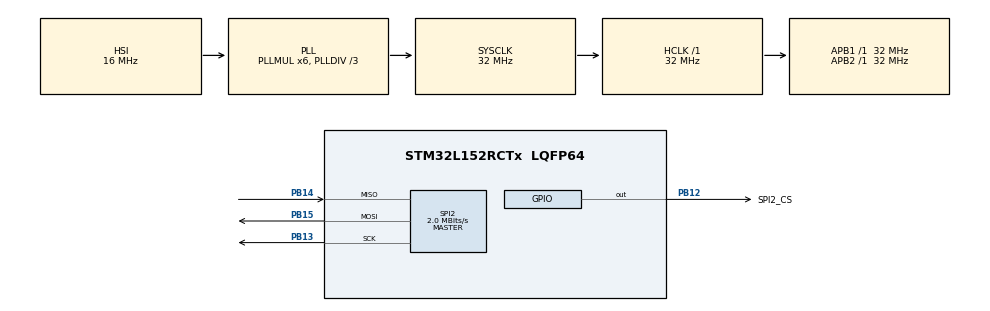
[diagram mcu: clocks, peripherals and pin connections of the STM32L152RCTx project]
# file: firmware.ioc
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Mcu.Family=STM32L1
Mcu.Name=STM32L152RCTx
Mcu.Package=LQFP64
NVIC.PriorityGroup=NVIC_PRIORITYGROUP_4
PB12.GPIO_Label=SPI2_CS
PB12.GPIO_PuPd=GPIO_PULLUP
PB12.GPIO_Speed=GPIO_SPEED_FREQ_VERY_HIGH
PB12.PinState=GPIO_PIN_SET
PB12.Signal=GPIO_Output
PB13.GPIO_PuPd=GPIO_PULLUP
PB13.Mode=Full_Duplex_Master
PB13.Signal=SPI2_SCK
PB14.GPIO_PuPd=GPIO_PULLUP
PB14.Mode=Full_Duplex_Master
PB14.Signal=SPI2_MISO
PB15.GPIO_PuPd=GPIO_PULLUP
PB15.Mode=Full_Duplex_Master
PB15.Signal=SPI2_MOSI
ProjectManager.HeapSize=0x200
ProjectManager.StackSize=0x400
ProjectManager.TargetToolchain=MDK-ARM V5
RCC.AHBFreq_Value=32000000
RCC.APB1Freq_Value=32000000
RCC.APB1TimFreq_Value=32000000
RCC.APB2Freq_Value=32000000
RCC.APB2TimFreq_Value=32000000
RCC.HCLKFreq_Value=32000000
RCC.HSE_VALUE=24000000
RCC.HSI_VALUE=16000000
RCC.LSE_VALUE=32768
RCC.MSI_VALUE=2097000
RCC.PLLDIV=RCC_PLL_DIV3
RCC.PLLMUL=RCC_PLL_MUL6
RCC.SYSCLKFreq_VALUE=32000000
RCC.SYSCLKSource=RCC_SYSCLKSOURCE_PLLCLK
RCC.USBOutput=48000000
RCC.VCOOutputFreq_Value=96000000
SPI2.BaudRatePrescaler=SPI_BAUDRATEPRESCALER_16
SPI2.CRCCalculation=SPI_CRCCALCULATION_DISABLE
SPI2.CalculateBaudRate=2.0 MBits/s
SPI2.Direction=SPI_DIRECTION_2LINES
SPI2.Mode=SPI_MODE_MASTER
SPI2.VirtualType=VM_MASTER
VP_FATFS_VS_Generic.Mode=User_defined
board=firmware

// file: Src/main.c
/**
  ******************************************************************************
  * File Name          : main.c
  * Description        : Main program body
  ******************************************************************************
  * This notice applies to any and all portions of this file
  * that are not between comment pairs USER CODE BEGIN and
  * USER CODE END. Other portions of this file, whether
  * inserted by the user or by software development tools
  * are owned by their respective copyright owners.
  *
  * Copyright (c) 2017 STMicroelectronics International N.V.
  * All rights reserved.
  *
  * Redistribution and use in source and binary forms, with or without
  * modification, are permitted, provided that the following conditions are met:
  *
  * 1. Redistribution of source code must retain the above copyright notice,
  *    this list of conditions and the following disclaimer.
  * 2. Redistributions in binary form must reproduce the above copyright notice,
  *    this list of conditions and the following disclaimer in the documentation
  *    and/or other materials provided with the distribution.
  * 3. Neither the name of STMicroelectronics nor the names of other
  *    contributors to this software may be used to endorse or promote products
  *    derived from this software without specific written permission.
  * 4. This software, including modifications and/or derivative works of this
  *    software, must execute solely and exclusively on microcontroller or
  *    microprocessor devices manufactured by or for STMicroelectronics.
  * 5. Redistribution and use of this software other than as permitted under
  *    this license is void and will automatically terminate your rights under
  *    this license.
  *
  * THIS SOFTWARE IS PROVIDED BY STMICROELECTRONICS AND CONTRIBUTORS "AS IS"
  * AND ANY EXPRESS, IMPLIED OR STATUTORY WARRANTIES, INCLUDING, BUT NOT
  * LIMITED TO, THE IMPLIED WARRANTIES OF MERCHANTABILITY, FITNESS FOR A
  * PARTICULAR PURPOSE AND NON-INFRINGEMENT OF THIRD PARTY INTELLECTUAL PROPERTY
  * RIGHTS ARE DISCLAIMED TO THE FULLEST EXTENT PERMITTED BY LAW. IN NO EVENT
  * SHALL STMICROELECTRONICS OR CONTRIBUTORS BE LIABLE FOR ANY DIRECT, INDIRECT,
  * INCIDENTAL, SPECIAL, EXEMPLARY, OR CONSEQUENTIAL DAMAGES (INCLUDING, BUT NOT
  * LIMITED TO, PROCUREMENT OF SUBSTITUTE GOODS OR SERVICES; LOSS OF USE, DATA,
  * OR PROFITS; OR BUSINESS INTERRUPTION) HOWEVER CAUSED AND ON ANY THEORY OF
  * LIABILITY, WHETHER IN CONTRACT, STRICT LIABILITY, OR TORT (INCLUDING
  * NEGLIGENCE OR OTHERWISE) ARISING IN ANY WAY OUT OF THE USE OF THIS SOFTWARE,
  * EVEN IF ADVISED OF THE POSSIBILITY OF SUCH DAMAGE.
  *
  ******************************************************************************
  */
#include "main.h"
#include "stm32l1xx_hal.h"
#include "fatfs.h"
#include "spi.h"
#include "gpio.h"

/* USER CODE BEGIN Includes */

#include "git_sha.h"

/* USER CODE END Includes */

/* USER CODE BEGIN PV */
/* Private variables ---------------------------------------------------------*/

/* USER CODE END PV */

void SystemClock_Config(void);

/* USER CODE BEGIN PFP */
/* Private function prototypes -----------------------------------------------*/

/* USER CODE END PFP */

int main(void)
{

  /* MCU Configuration----------------------------------------------------------*/

  /* Reset of all peripherals, Initializes the Flash interface and the Systick. */
  HAL_Init();

  /* Configure the system clock */
  SystemClock_Config();

  /* Initialize all configured peripherals */
  MX_GPIO_Init();
  MX_FATFS_Init();
	MX_SPI2_Init();

  USER_initialize(0);

  uint8_t array_data[512];

  for(int i = 0; i<512; i++)
  {
    if(i%2==0)
      array_data[i]=0x44;
    else
      array_data[i]=0x45;
  }

  DWORD address = 0x00000000;
  uint8_t count = 1;

  USER_write(0,array_data,address,count);

  /* Infinite loop */
  while (1)
  {

  }

}

/** System Clock Configuration
*/
void SystemClock_Config(void)
{

  RCC_OscInitTypeDef RCC_OscInitStruct;
  RCC_ClkInitTypeDef RCC_ClkInitStruct;

    /**Configure the main internal regulator output voltage
    */
  __HAL_PWR_VOLTAGESCALING_CONFIG(PWR_REGULATOR_VOLTAGE_SCALE1);

    /**Initializes the CPU, AHB and APB busses clocks
    */
  RCC_OscInitStruct.OscillatorType = RCC_OSCILLATORTYPE_HSI;
  RCC_OscInitStruct.HSIState = RCC_HSI_ON;
  RCC_OscInitStruct.HSICalibrationValue = 16;
  RCC_OscInitStruct.PLL.PLLState = RCC_PLL_ON;
  RCC_OscInitStruct.PLL.PLLSource = RCC_PLLSOURCE_HSI;
  RCC_OscInitStruct.PLL.PLLMUL = RCC_PLL_MUL6;
  RCC_OscInitStruct.PLL.PLLDIV = RCC_PLL_DIV3;
  if (HAL_RCC_OscConfig(&RCC_OscInitStruct) != HAL_OK)
  {
    _Error_Handler(__FILE__, __LINE__);
  }

    /**Initializes the CPU, AHB and APB busses clocks
    */
  RCC_ClkInitStruct.ClockType = RCC_CLOCKTYPE_HCLK|RCC_CLOCKTYPE_SYSCLK
                              |RCC_CLOCKTYPE_PCLK1|RCC_CLOCKTYPE_PCLK2;
  RCC_ClkInitStruct.SYSCLKSource = RCC_SYSCLKSOURCE_PLLCLK;
  RCC_ClkInitStruct.AHBCLKDivider = RCC_SYSCLK_DIV1;
  RCC_ClkInitStruct.APB1CLKDivider = RCC_HCLK_DIV1;
  RCC_ClkInitStruct.APB2CLKDivider = RCC_HCLK_DIV1;

  if (HAL_RCC_ClockConfig(&RCC_ClkInitStruct, FLASH_LATENCY_1) != HAL_OK)
  {
    _Error_Handler(__FILE__, __LINE__);
  }

    /**Configure the Systick interrupt time
    */
  HAL_SYSTICK_Config(HAL_RCC_GetHCLKFreq()/1000);

    /**Configure the Systick
    */
  HAL_SYSTICK_CLKSourceConfig(SYSTICK_CLKSOURCE_HCLK);

  /* SysTick_IRQn interrupt configuration */
  HAL_NVIC_SetPriority(SysTick_IRQn, 0, 0);
}

void _Error_Handler(char * file, int line)
{
  while(1)
  {
  }
}

/************************ (C) COPYRIGHT STMicroelectronics *****END OF FILE****/
